VERSION ""

NS_ :

BS_:

BU_:

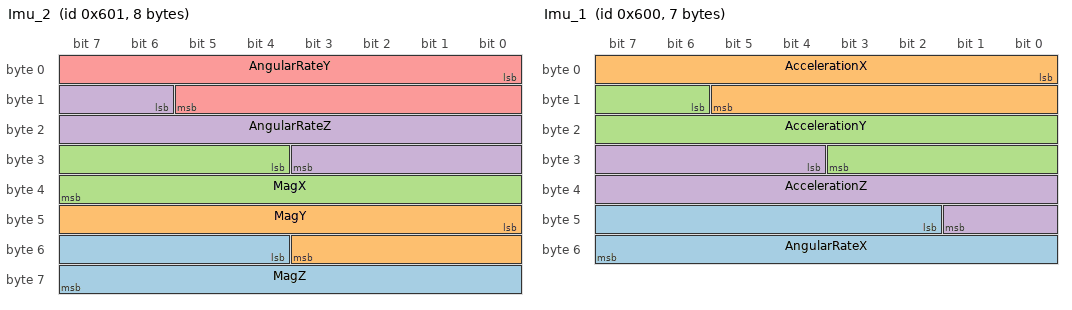
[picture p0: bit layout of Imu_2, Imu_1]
BO_ 1537 Imu_2: 8 Vector__XXX
 SG_ MagZ : 52|12@1- (0.3,0) [-614.4|614.1] "uT" Vector__XXX
 SG_ MagY : 40|12@1- (0.3,0) [-614.4|614.1] "uT" Vector__XXX
 SG_ MagX : 28|12@1- (0.3,0) [-614.4|614.1] "uT" Vector__XXX
 SG_ AngularRateZ : 14|14@1- (0.0625,0) [-512|511.9375] "deg/s" Vector__XXX
 SG_ AngularRateY : 0|14@1- (0.0625,0) [-512|511.9375] "deg/s" Vector__XXX

BO_ 1536 Imu_1: 7 Vector__XXX
 SG_ AngularRateX : 42|14@1- (0.0625,0) [-512|511.9375] "deg/s" Vector__XXX
 SG_ AccelerationX : 0|14@1- (0.001,0) [-8.192|8.191] "m/s^2" Vector__XXX
 SG_ AccelerationY : 14|14@1- (0.001,0) [-8.192|8.19175] "m/s^2" Vector__XXX
 SG_ AccelerationZ : 28|14@1- (0.001,0) [-8.192|8.191] "m/s^2" Vector__XXX

CM_ BO_ 1537 "IMU";
CM_ SG_ 1537 MagZ "X magnetometer reading";
CM_ SG_ 1537 MagY "X magnetometer reading";
CM_ SG_ 1537 MagX "X magnetometer reading";
CM_ SG_ 1537 AngularRateZ "Z angular rate";
CM_ SG_ 1537 AngularRateY "Y angular rate";
CM_ BO_ 1536 "IMU";
CM_ SG_ 1536 AngularRateX "X angular rate";
CM_ SG_ 1536 AccelerationX "X acceleration";
CM_ SG_ 1536 AccelerationY "Y acceleration";
CM_ SG_ 1536 AccelerationZ "Z acceleration";
BA_DEF_  "BusType" STRING ;
BA_DEF_  "ProtocolType" STRING ;
BA_DEF_DEF_  "BusType" "";
BA_DEF_DEF_  "ProtocolType" "";
BA_ "BusType" "CAN";
